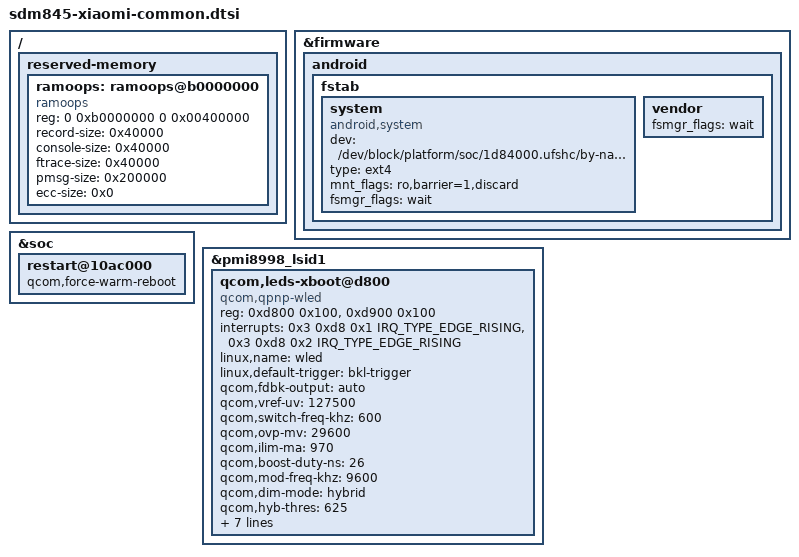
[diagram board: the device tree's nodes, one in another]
/* Copyright (c) 2016-2018, The Linux Foundation. All rights reserved.
 * Copyright (C) 2018 XiaoMi, Inc.
 *
 * This program is free software; you can redistribute it and/or modify
 * it under the terms of the GNU General Public License version 2 and
 * only version 2 as published by the Free Software Foundation.
 *
 * This program is distributed in the hope that it will be useful,
 * but WITHOUT ANY WARRANTY; without even the implied warranty of
 * MERCHANTABILITY or FITNESS FOR A PARTICULAR PURPOSE.  See the
 * GNU General Public License for more details.
 */

#include "sdm845-xiaomi-sde-display.dtsi"

/{
	reserved-memory {
		ramoops: ramoops@b0000000 {
			compatible = "ramoops";
			reg = <0 0xb0000000 0 0x00400000>;
			record-size = <0x40000>; /*256x1024*/
			console-size = <0x40000>;
			ftrace-size = <0x40000>;
			pmsg-size = <0x200000>;
			ecc-size = <0x0>;
		};
	};
};

&firmware {
	android {
		/delete-node/ vbmeta;

		fstab {
			system {
				compatible = "android,system";
				dev = "/dev/block/platform/soc/1d84000.ufshc/by-name/system";
				type = "ext4";
				mnt_flags = "ro,barrier=1,discard";
				fsmgr_flags = "wait";
				status = "ok";
			};
			vendor {
				fsmgr_flags = "wait";
			};
			/delete-node/ odm;
		};
	};
};
/*
&red_led {
	linux,name = "white";
	qcom,start-idx = <1>;
	qcom,idx-len = <11>;
	qcom,duty-pcts = [00 05 0a 0f 14 1d 28 32 3c 4b 64];
	qcom,lut-flags = <0x1f>;
	qcom,pause-lo = <2000>;
	qcom,pause-hi = <1000>;
	qcom,ramp-step-ms = <100>;
	qcom,use-blink;
	status = "okay";
};

&green_led {
	status = "disabled";
};

&blue_led {
	status = "disabled";
};
*/

&soc {
	restart@10ac000 {
		qcom,force-warm-reboot;
	};
};

&pmi8998_lsid1 {
	qcom,leds-xboot@d800 {
		compatible = "qcom,qpnp-wled";
		reg = <0xd800 0x100>,
		      <0xd900 0x100>;
		reg-names = "qpnp-wled-ctrl-base",
			    "qpnp-wled-sink-base";
		interrupts = <0x3 0xd8 0x1 IRQ_TYPE_EDGE_RISING>,
			     <0x3 0xd8 0x2 IRQ_TYPE_EDGE_RISING>;
		interrupt-names = "ovp-irq", "sc-irq";
		linux,name = "wled";
		linux,default-trigger = "bkl-trigger";
		qcom,fdbk-output = "auto";
		qcom,vref-uv = <127500>;
		qcom,switch-freq-khz = <600>;
		qcom,ovp-mv = <29600>;
		qcom,ilim-ma = <970>;
		qcom,boost-duty-ns = <26>;
		qcom,mod-freq-khz = <9600>;
		qcom,dim-mode = "hybrid";
		qcom,hyb-thres = <625>;
		qcom,sync-dly-us = <800>;
		qcom,fs-curr-ua = <20000>;
		qcom,cons-sync-write-delay-us = <1000>;
		qcom,led-strings-list = [00 01];
		qcom,en-ext-pfet-sc-pro;
		qcom,pmic-revid = <&pmi8998_revid>;
		qcom,loop-auto-gm-en;
		status = "okay";
	};
};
